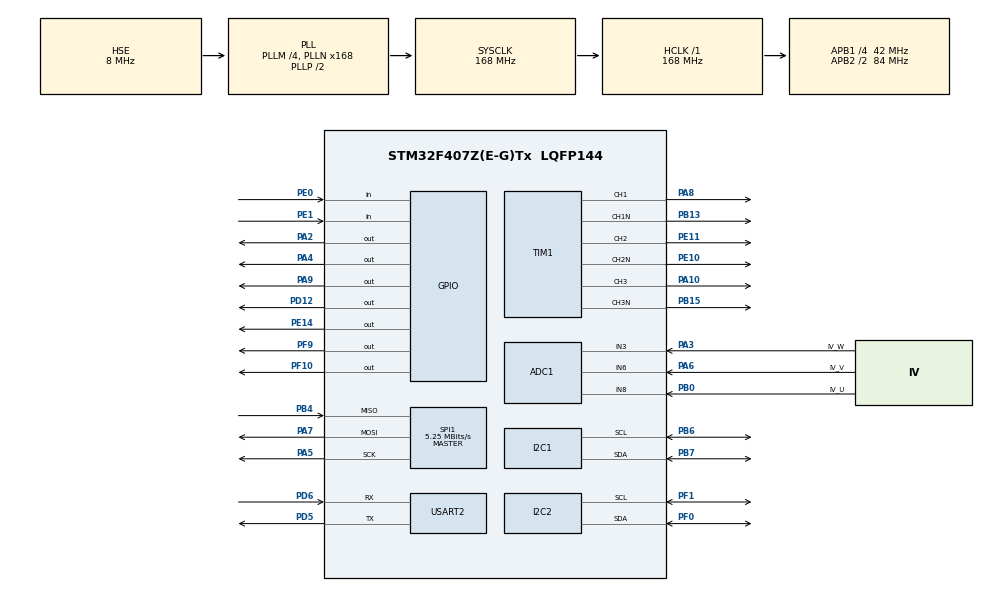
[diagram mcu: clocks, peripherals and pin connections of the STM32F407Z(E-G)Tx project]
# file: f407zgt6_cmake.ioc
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ADC1.Channel-0\#ChannelRegularConversion=ADC_CHANNEL_3
ADC1.Channel-10\#ChannelInjectedConversion=ADC_CHANNEL_3
ADC1.Channel-15\#ChannelInjectedConversion=ADC_CHANNEL_6
ADC1.Channel-16\#ChannelInjectedConversion=ADC_CHANNEL_8
ADC1.ClockPrescaler=ADC_CLOCK_SYNC_PCLK_DIV4
ADC1.DMAContinuousRequests=DISABLE
ADC1.DiscontinuousConvMode=DISABLE
ADC1.ExternalTrigConv=ADC_SOFTWARE_START
ADC1.ExternalTrigInjecConv=ADC_EXTERNALTRIGINJECCONV_T1_CC4
ADC1.ExternalTrigInjecConvEdge=ADC_EXTERNALTRIGINJECCONVEDGE_FALLING
ADC1.InjNumberOfConversion=3
ADC1.InjectedConvMode=None
ADC1.InjectedOffset-10\#ChannelInjectedConversion=0
ADC1.InjectedOffset-15\#ChannelInjectedConversion=0
ADC1.InjectedOffset-16\#ChannelInjectedConversion=0
ADC1.InjectedRank-10\#ChannelInjectedConversion=1
ADC1.InjectedRank-15\#ChannelInjectedConversion=2
ADC1.InjectedRank-16\#ChannelInjectedConversion=3
ADC1.NbrOfConversion=1
ADC1.NbrOfConversionFlag=1
ADC1.Rank-0\#ChannelRegularConversion=1
ADC1.SamplingTime-0\#ChannelRegularConversion=ADC_SAMPLETIME_3CYCLES
ADC1.SamplingTime-10\#ChannelInjectedConversion=ADC_SAMPLETIME_3CYCLES
ADC1.SamplingTime-15\#ChannelInjectedConversion=ADC_SAMPLETIME_3CYCLES
ADC1.SamplingTime-16\#ChannelInjectedConversion=ADC_SAMPLETIME_3CYCLES
ADC1.ScanConvMode=ENABLE
ADC1.master=1
Mcu.Family=STM32F4
Mcu.Name=STM32F407Z(E-G)Tx
Mcu.Package=LQFP144
NVIC.ADC_IRQn=true\:0\:0\:false\:false\:true\:true\:true\:true
NVIC.PriorityGroup=NVIC_PRIORITYGROUP_4
NVIC.TIM1_BRK_TIM9_IRQn=true\:0\:0\:false\:false\:true\:true\:true\:true
NVIC.TIM1_CC_IRQn=true\:0\:0\:false\:false\:true\:true\:true\:true
NVIC.TIM1_TRG_COM_TIM11_IRQn=true\:0\:0\:false\:false\:true\:true\:true\:true
NVIC.TIM1_UP_TIM10_IRQn=true\:0\:0\:false\:false\:true\:true\:true\:true
NVIC.TIM2_IRQn=true\:0\:0\:false\:false\:true\:true\:true\:true
NVIC.TIM3_IRQn=true\:0\:0\:false\:false\:true\:true\:true\:true
NVIC.TIM8_BRK_TIM12_IRQn=true\:0\:0\:false\:false\:true\:true\:true\:true
NVIC.TIM8_CC_IRQn=true\:0\:0\:false\:false\:true\:true\:true\:true
NVIC.TIM8_TRG_COM_TIM14_IRQn=true\:0\:0\:false\:false\:true\:true\:true\:true
NVIC.TIM8_UP_TIM13_IRQn=true\:0\:0\:false\:false\:true\:true\:true\:true
NVIC.USART2_IRQn=true\:0\:0\:false\:false\:true\:true\:true\:true
PA10.Signal=S_TIM1_CH3
PA13.Mode=Serial_Wire
PA13.Signal=SYS_JTMS-SWDIO
PA14.Mode=Serial_Wire
PA14.Signal=SYS_JTCK-SWCLK
PA2.Signal=GPIO_Output
PA3.GPIO_Label=IV_W
PA3.Signal=ADCx_IN3
PA4.Signal=GPIO_Output
PA5.Mode=Full_Duplex_Master
PA5.Signal=SPI1_SCK
PA6.GPIO_Label=IV_V
PA6.Signal=ADCx_IN6
PA7.Mode=Full_Duplex_Master
PA7.Signal=SPI1_MOSI
PA8.Signal=S_TIM1_CH1
PA9.Signal=GPIO_Output
PB0.GPIO_Label=IV_U
PB0.Signal=ADCx_IN8
PB1.Signal=ADCx_IN9
PB13.Mode=PWM Generation1 CH1 CH1N
PB13.Signal=TIM1_CH1N
PB15.Mode=PWM Generation3 CH3 CH3N
PB15.Signal=TIM1_CH3N
PB4.Mode=Full_Duplex_Master
PB4.Signal=SPI1_MISO
PB6.Mode=I2C
PB6.Signal=I2C1_SCL
PB7.Mode=I2C
PB7.Signal=I2C1_SDA
PD12.Signal=GPIO_Output
PD5.Mode=Asynchronous
PD5.Signal=USART2_TX
PD6.Mode=Asynchronous
PD6.Signal=USART2_RX
PE0.GPIO_PuPd=GPIO_PULLDOWN
PE0.Signal=GPIO_Input
PE1.GPIO_PuPd=GPIO_PULLDOWN
PE1.Signal=GPIO_Input
PE10.Mode=PWM Generation2 CH2 CH2N
PE10.Signal=TIM1_CH2N
PE11.Signal=S_TIM1_CH2
PE14.Signal=GPIO_Output
PF0.Mode=I2C
PF0.Signal=I2C2_SDA
PF1.Mode=I2C
PF1.Signal=I2C2_SCL
PF10.Signal=GPIO_Output
PF9.Signal=GPIO_Output
PH0-OSC_IN.Mode=HSE-External-Oscillator
PH0-OSC_IN.Signal=RCC_OSC_IN
PH1-OSC_OUT.Mode=HSE-External-Oscillator
PH1-OSC_OUT.Signal=RCC_OSC_OUT
ProjectManager.HeapSize=0x200
ProjectManager.StackSize=0x400
ProjectManager.TargetToolchain=CMake
RCC.48MHZClocksFreq_Value=84000000
RCC.AHBFreq_Value=168000000
RCC.APB1CLKDivider=RCC_HCLK_DIV4
RCC.APB1Freq_Value=42000000
RCC.APB1TimFreq_Value=84000000
RCC.APB2CLKDivider=RCC_HCLK_DIV2
RCC.APB2Freq_Value=84000000
RCC.APB2TimFreq_Value=168000000
RCC.CortexFreq_Value=168000000
RCC.HCLKFreq_Value=168000000
RCC.HSE_VALUE=8000000
RCC.HSI_VALUE=16000000
RCC.LSE_VALUE=32768
RCC.PLLM=4
RCC.PLLN=168
RCC.PLLSourceVirtual=RCC_PLLSOURCE_HSE
RCC.SYSCLKFreq_VALUE=168000000
RCC.SYSCLKSource=RCC_SYSCLKSOURCE_PLLCLK
RCC.VCOOutputFreq_Value=336000000
SH.ADCx_IN3.0=ADC1_IN3,IN3
SH.ADCx_IN6.0=ADC1_IN6,IN6
SH.ADCx_IN8.0=ADC1_IN8,IN8
SH.ADCx_IN9.0=ADC1_IN9
SH.S_TIM1_CH1.0=TIM1_CH1,PWM Generation1 CH1 CH1N
SH.S_TIM1_CH2.0=TIM1_CH2,PWM Generation2 CH2 CH2N
SH.S_TIM1_CH3.0=TIM1_CH3,PWM Generation3 CH3 CH3N
SPI1.BaudRatePrescaler=SPI_BAUDRATEPRESCALER_16
SPI1.CLKPolarity=SPI_POLARITY_HIGH
SPI1.CalculateBaudRate=5.25 MBits/s
SPI1.Direction=SPI_DIRECTION_2LINES
SPI1.Mode=SPI_MODE_MASTER
SPI1.VirtualType=VM_MASTER
TIM1.AutoReloadPreload=TIM_AUTORELOAD_PRELOAD_ENABLE
TIM1.Channel-PWM\ Generation1\ CH1\ CH1N=TIM_CHANNEL_1
TIM1.Channel-PWM\ Generation2\ CH2\ CH2N=TIM_CHANNEL_2
TIM1.Channel-PWM\ Generation3\ CH3\ CH3N=TIM_CHANNEL_3
TIM1.Channel-PWM\ Generation4\ No\ Output=TIM_CHANNEL_4
TIM1.CounterMode=TIM_COUNTERMODE_CENTERALIGNED1
TIM1.DeadTime=100
TIM1.OCMode_PWM-PWM\ Generation1\ CH1\ CH1N=TIM_OCMODE_PWM2
TIM1.OCMode_PWM-PWM\ Generation2\ CH2\ CH2N=TIM_OCMODE_PWM2
TIM1.OCMode_PWM-PWM\ Generation3\ CH3\ CH3N=TIM_OCMODE_PWM2
TIM1.OCMode_PWM-PWM\ Generation4\ No\ Output=TIM_OCMODE_PWM1
TIM1.RepetitionCounter=1
TIM1.TIM_MasterOutputTrigger=TIM_TRGO_OC4REF
TIM2.AutoReloadPreload=TIM_AUTORELOAD_PRELOAD_ENABLE
TIM2.Period=99
TIM2.Prescaler=83
TIM2.TIM_MasterOutputTrigger=TIM_TRGO_UPDATE
TIM3.AutoReloadPreload=TIM_AUTORELOAD_PRELOAD_ENABLE
TIM3.Period=999
TIM3.Prescaler=83
TIM3.TIM_MasterOutputTrigger=TIM_TRGO_UPDATE
USART2.VirtualMode=VM_ASYNC
VP_TIM1_VS_ClockSourceINT.Mode=Internal
VP_TIM1_VS_no_output4.Mode=PWM Generation4 No Output
VP_TIM2_VS_ClockSourceINT.Mode=Internal
VP_TIM3_VS_ClockSourceINT.Mode=Internal
VP_TIM8_VS_ClockSourceINT.Mode=Internal
board=custom

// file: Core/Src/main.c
/* USER CODE BEGIN Header */
/**
  ******************************************************************************
  * @file           : main.c
  * @brief          : Main program body
  ******************************************************************************
  * @attention
  *
  * Copyright (c) 2025 STMicroelectronics.
  * All rights reserved.
  *
  * This software is licensed under terms that can be found in the LICENSE file
  * in the root directory of this software component.
  * If no LICENSE file comes with this software, it is provided AS-IS.
  *
  ******************************************************************************
  */
/* USER CODE END Header */
#include "main.h"
#include "adc.h"
#include "i2c.h"
#include "spi.h"
#include "tim.h"
#include "usart.h"
#include "gpio.h"

/* USER CODE BEGIN Includes */
#include <stdio.h>

/* USER CODE END Includes */

void SystemClock_Config(void);

/* USER CODE BEGIN 0 */
extern void test_main(void);

/* USER CODE END 0 */

int main(void)
{

  /* MCU Configuration--------------------------------------------------------*/

  /* Reset of all peripherals, Initializes the Flash interface and the Systick. */
  HAL_Init();

  /* Configure the system clock */
  SystemClock_Config();

  /* Initialize all configured peripherals */
  MX_GPIO_Init();
  MX_USART2_UART_Init();
  MX_ADC1_Init();
  MX_I2C1_Init();
  MX_TIM1_Init();
  MX_TIM8_Init();
  MX_I2C2_Init();
  MX_SPI1_Init();
  MX_TIM3_Init();
  MX_TIM2_Init();
  /* USER CODE BEGIN 2 */
    test_main();

  /* USER CODE END 2 */

  /* Infinite loop */
  while (1)
  {

    /* USER CODE BEGIN 3 */
      HAL_GPIO_TogglePin(GPIOF, GPIO_PIN_9);
      printf("hello motor cmake\n");
      HAL_Delay(500);
  }
  /* USER CODE END 3 */
}

void SystemClock_Config(void)
{
  RCC_OscInitTypeDef RCC_OscInitStruct = {0};
  RCC_ClkInitTypeDef RCC_ClkInitStruct = {0};

  /** Configure the main internal regulator output voltage
  */
  __HAL_RCC_PWR_CLK_ENABLE();
  __HAL_PWR_VOLTAGESCALING_CONFIG(PWR_REGULATOR_VOLTAGE_SCALE1);

  /** Initializes the RCC Oscillators according to the specified parameters
  * in the RCC_OscInitTypeDef structure.
  */
  RCC_OscInitStruct.OscillatorType = RCC_OSCILLATORTYPE_HSE;
  RCC_OscInitStruct.HSEState = RCC_HSE_ON;
  RCC_OscInitStruct.PLL.PLLState = RCC_PLL_ON;
  RCC_OscInitStruct.PLL.PLLSource = RCC_PLLSOURCE_HSE;
  RCC_OscInitStruct.PLL.PLLM = 4;
  RCC_OscInitStruct.PLL.PLLN = 168;
  RCC_OscInitStruct.PLL.PLLP = RCC_PLLP_DIV2;
  RCC_OscInitStruct.PLL.PLLQ = 4;
  if (HAL_RCC_OscConfig(&RCC_OscInitStruct) != HAL_OK)
  {
    Error_Handler();
  }

  /** Initializes the CPU, AHB and APB buses clocks
  */
  RCC_ClkInitStruct.ClockType = RCC_CLOCKTYPE_HCLK|RCC_CLOCKTYPE_SYSCLK
                              |RCC_CLOCKTYPE_PCLK1|RCC_CLOCKTYPE_PCLK2;
  RCC_ClkInitStruct.SYSCLKSource = RCC_SYSCLKSOURCE_PLLCLK;
  RCC_ClkInitStruct.AHBCLKDivider = RCC_SYSCLK_DIV1;
  RCC_ClkInitStruct.APB1CLKDivider = RCC_HCLK_DIV4;
  RCC_ClkInitStruct.APB2CLKDivider = RCC_HCLK_DIV2;

  if (HAL_RCC_ClockConfig(&RCC_ClkInitStruct, FLASH_LATENCY_5) != HAL_OK)
  {
    Error_Handler();
  }
}

void Error_Handler(void)
{
  __disable_irq();
  while (1)
  {
  }
}
